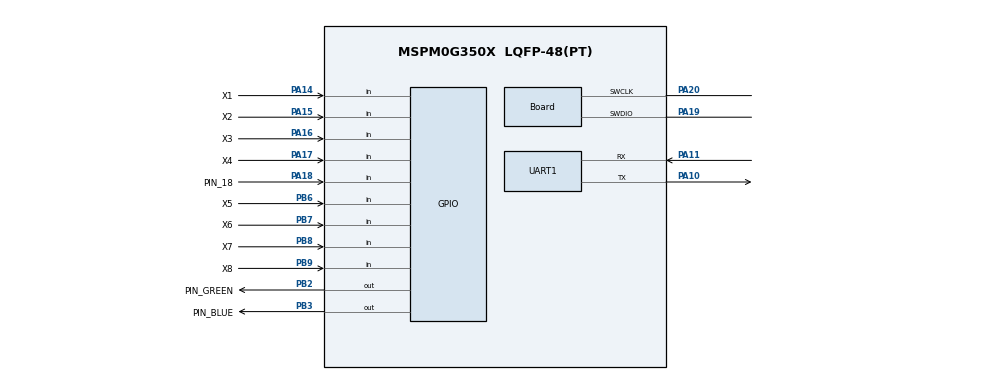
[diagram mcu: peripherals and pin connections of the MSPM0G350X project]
/**
 *
 * @cliArgs --device "MSPM0G350X" --part "Default" --package "LQFP-48(PT)" --product "mspm0_sdk@2.10.00.04"
 * @versions {"tool":"1.28.0+4712"}
 */

/**
 * Import the modules used in this configuration.
 */
const GPIO   = scripting.addModule("/ti/driverlib/GPIO", {}, false);
const GPIO1  = GPIO.addInstance();
const GPIO2  = GPIO.addInstance();
const GPIO3  = GPIO.addInstance();
const GPIO4  = GPIO.addInstance();
const GPIO5  = GPIO.addInstance();
const SYSCTL = scripting.addModule("/ti/driverlib/SYSCTL");
const UART   = scripting.addModule("/ti/driverlib/UART", {}, false);
const UART1  = UART.addInstance();

/**
 * Write custom configuration values to the imported modules.
 */
GPIO1.$name                              = "LED_BLUE";
GPIO1.port                               = "PORTB";
GPIO1.associatedPins[0].$name            = "PIN_BLUE";
GPIO1.associatedPins[0].internalResistor = "PULL_DOWN";
GPIO1.associatedPins[0].assignedPin      = "3";
GPIO1.associatedPins[0].pin.$assign      = "PB3";

const Board                       = scripting.addModule("/ti/driverlib/Board", {}, false);
Board.peripheral.$assign          = "DEBUGSS";
Board.peripheral.swclkPin.$assign = "PA20";
Board.peripheral.swdioPin.$assign = "PA19";

GPIO2.$name                              = "KEY";
GPIO2.port                               = "PORTA";
GPIO2.associatedPins[0].$name            = "PIN_18";
GPIO2.associatedPins[0].direction        = "INPUT";
GPIO2.associatedPins[0].internalResistor = "PULL_DOWN";
GPIO2.associatedPins[0].assignedPin      = "18";
GPIO2.associatedPins[0].pin.$assign      = "PA18";

GPIO3.$name                              = "LED_GREEN";
GPIO3.port                               = "PORTB";
GPIO3.associatedPins[0].$name            = "PIN_GREEN";
GPIO3.associatedPins[0].internalResistor = "PULL_DOWN";
GPIO3.associatedPins[0].assignedPin      = "2";
GPIO3.associatedPins[0].pin.$assign      = "PB2";

/* 8-ch IR line sensor — left half (X1..X4, leftmost → rightmost) */
GPIO4.$name                              = "LINE8_LEFT";
GPIO4.port                               = "PORTA";
GPIO4.associatedPins.create(4);
GPIO4.associatedPins[0].$name            = "X1";
GPIO4.associatedPins[0].direction        = "INPUT";
GPIO4.associatedPins[0].assignedPin      = "14";
GPIO4.associatedPins[0].pin.$assign      = "PA14";
GPIO4.associatedPins[1].$name            = "X2";
GPIO4.associatedPins[1].direction        = "INPUT";
GPIO4.associatedPins[1].assignedPin      = "15";
GPIO4.associatedPins[1].pin.$assign      = "PA15";
GPIO4.associatedPins[2].$name            = "X3";
GPIO4.associatedPins[2].direction        = "INPUT";
GPIO4.associatedPins[2].assignedPin      = "16";
GPIO4.associatedPins[2].pin.$assign      = "PA16";
GPIO4.associatedPins[3].$name            = "X4";
GPIO4.associatedPins[3].direction        = "INPUT";
GPIO4.associatedPins[3].assignedPin      = "17";
GPIO4.associatedPins[3].pin.$assign      = "PA17";

/* 8-ch IR line sensor — right half (X5..X8, leftmost → rightmost) */
GPIO5.$name                              = "LINE8_RIGHT";
GPIO5.port                               = "PORTB";
GPIO5.associatedPins.create(4);
GPIO5.associatedPins[0].$name            = "X5";
GPIO5.associatedPins[0].direction        = "INPUT";
GPIO5.associatedPins[0].assignedPin      = "6";
GPIO5.associatedPins[0].pin.$assign      = "PB6";
GPIO5.associatedPins[1].$name            = "X6";
GPIO5.associatedPins[1].direction        = "INPUT";
GPIO5.associatedPins[1].assignedPin      = "7";
GPIO5.associatedPins[1].pin.$assign      = "PB7";
GPIO5.associatedPins[2].$name            = "X7";
GPIO5.associatedPins[2].direction        = "INPUT";
GPIO5.associatedPins[2].assignedPin      = "8";
GPIO5.associatedPins[2].pin.$assign      = "PB8";
GPIO5.associatedPins[3].$name            = "X8";
GPIO5.associatedPins[3].direction        = "INPUT";
GPIO5.associatedPins[3].assignedPin      = "9";
GPIO5.associatedPins[3].pin.$assign      = "PB9";

SYSCTL.forceDefaultClkConfig = true;
SYSCTL.clockTreeEn           = true;

/* UART0: XDS110 debug backchannel (PA10 TX / PA11 RX) */
UART1.$name                             = "UART_0";
UART1.enableFIFO                        = true;
UART1.enableDMARX                       = false;
UART1.enabledDMATXTriggers              = "DL_UART_DMA_INTERRUPT_TX";
UART1.targetBaudRate                    = 115200;
UART1.peripheral.$assign                = "UART0";
UART1.peripheral.rxPin.$assign          = "PA11";
UART1.peripheral.txPin.$assign          = "PA10";
UART1.txPinConfig.$name                 = "ti_driverlib_gpio_GPIOPinGeneric0";
UART1.rxPinConfig.$name                 = "ti_driverlib_gpio_GPIOPinGeneric1";
UART1.DMA_CHANNEL_TX.$name              = "DMA_CH0";
UART1.DMA_CHANNEL_TX.addressMode        = "b2f";
UART1.DMA_CHANNEL_TX.dstLength          = "BYTE";
UART1.DMA_CHANNEL_TX.srcLength          = "BYTE";
UART1.DMA_CHANNEL_TX.peripheral.$assign = "DMA_CH0";

const ProjectConfig              = scripting.addModule("/ti/project_config/ProjectConfig", {}, false);
ProjectConfig.migrationCondition = true;
